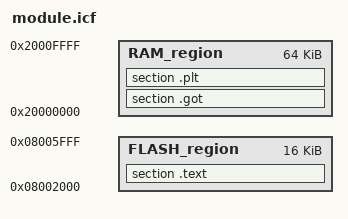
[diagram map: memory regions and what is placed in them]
define memory with size = 256K { FLASH };
define memory with size = 64K { RAM };
define region FLASH_region = mem:[from 0x08002000 size 16K];
define region RAM_region = mem:[from 0x20000000 size 64K];

place in FLASH_region { section .text };
place in RAM_region { section .got, section .plt };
